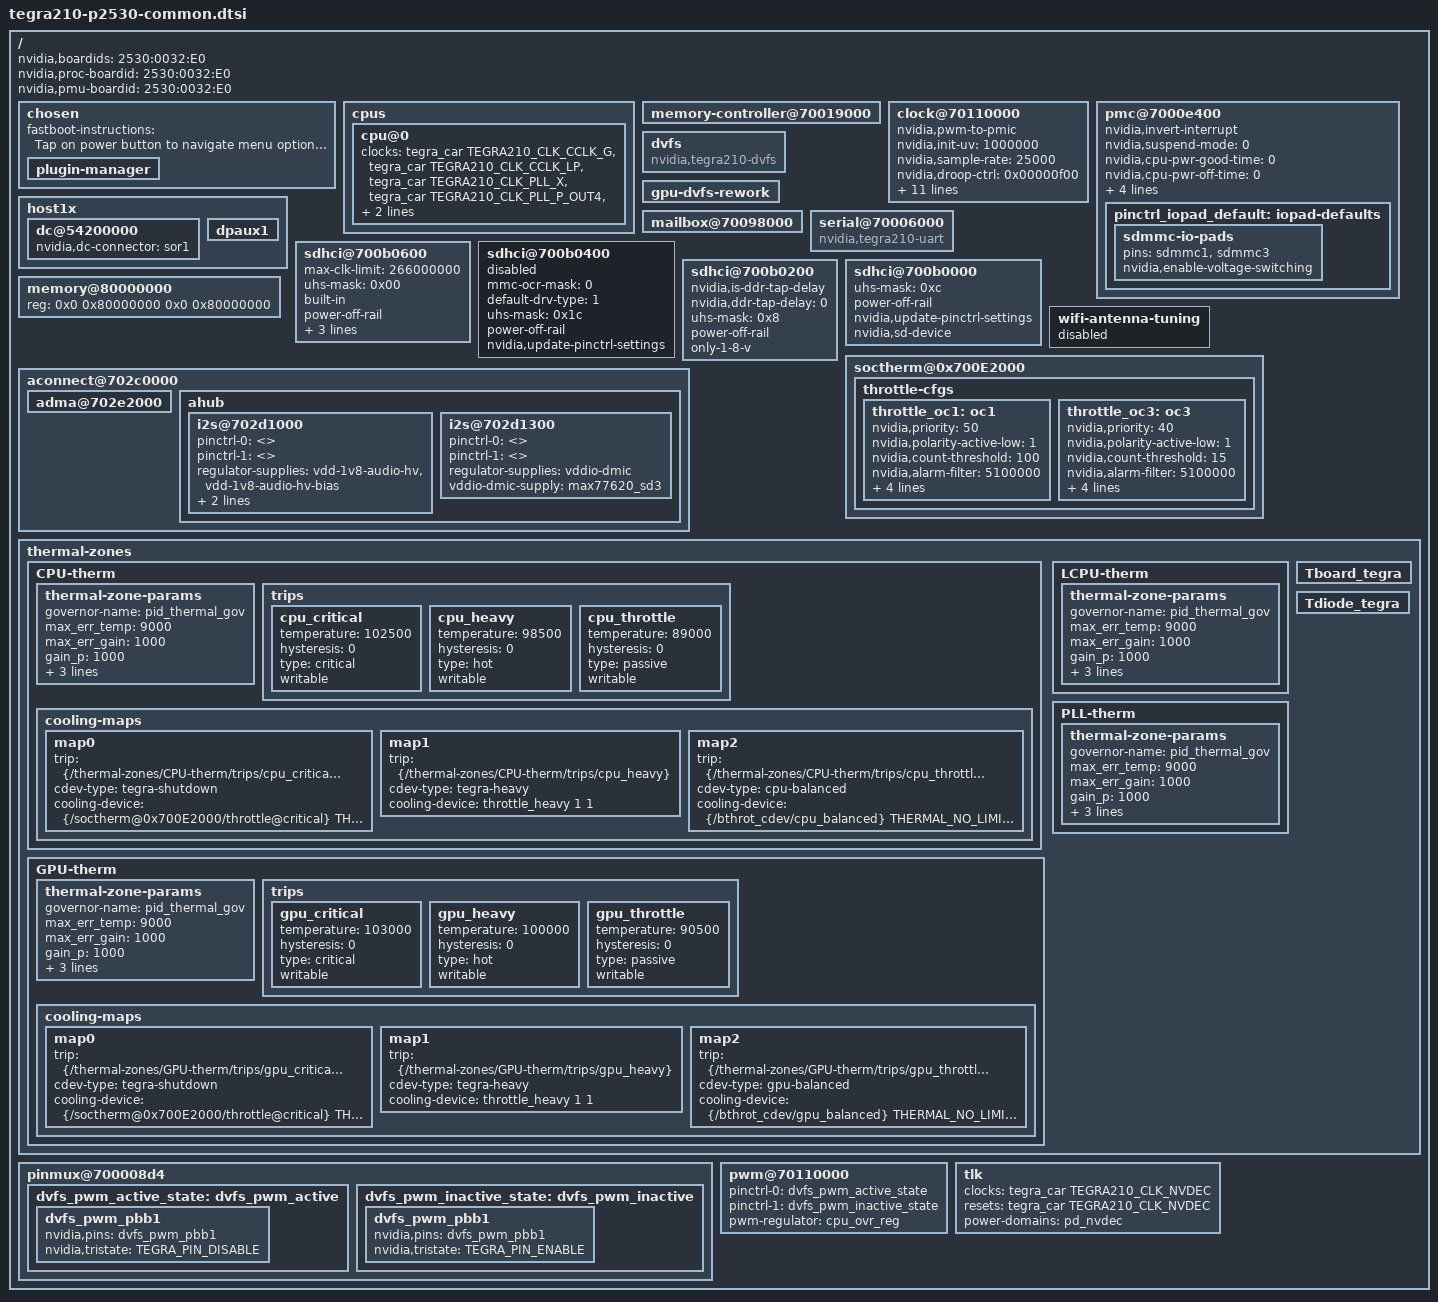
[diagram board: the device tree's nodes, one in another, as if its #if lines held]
/*
 * arch/arm64/boot/dts/tegra210-platforms/tegra210-p2530-common.dtsi
 *
 * Copyright (c) 2014 - 2017, NVIDIA CORPORATION.  All rights reserved.
 *
 * This program is free software; you can redistribute it and/or modify
 * it under the terms of the GNU General Public License as published by
 * the Free Software Foundation; version 2 of the License.
 *
 * This program is distributed in the hope that it will be useful, but WITHOUT
 * ANY WARRANTY; without even the implied warranty of MERCHANTABILITY or
 * FITNESS FOR A PARTICULAR PURPOSE.  See the GNU General Public License for
 * more details.
 *
 * You should have received a copy of the GNU General Public License along
 * with this program; if not, write to the Free Software Foundation, Inc.,
 * 51 Franklin Street, Fifth Floor, Boston, MA  02110-1301, USA.
 *
 */

#include <t210-common-platforms/tegra210-thermal-nct72-p2530.dtsi>
#include <tegra210-soc/tegra210-thermal-Tboard-Tdiode.dtsi>

/ {
	nvidia,boardids = "2530:0032:E0";
	nvidia,proc-boardid = "2530:0032:E0";
	nvidia,pmu-boardid = "2530:0032:E0";
	#address-cells = <2>;
	#size-cells = <2>;

	chosen {
		fastboot-instructions = "Tap on power button to navigate menu options.\nHold down power button for 2 sec and release for selecting an option\n";
		plugin-manager {
		};
	};

	cpus {
		cpu@0 {
			clocks = <&tegra_car TEGRA210_CLK_CCLK_G>,
				 <&tegra_car TEGRA210_CLK_CCLK_LP>,
				 <&tegra_car TEGRA210_CLK_PLL_X>,
				 <&tegra_car TEGRA210_CLK_PLL_P_OUT4>,
				 <&tegra_clk_dfll>;
			clock-names = "cpu_g", "cpu_lp", "pll_x", "pll_p", "dfll";
			clock-latency = <300000>;
		};
	};


	memory-controller@70019000 {
		status = "okay";
	};

	clock@70110000 {
		status = "okay";
		nvidia,pwm-to-pmic;
		nvidia,init-uv = <1000000>;
		nvidia,sample-rate = <25000>;
		nvidia,droop-ctrl = <0x00000f00>;
		nvidia,force-mode = <1>;
		nvidia,cf = <6>;
		nvidia,ci = <0>;
		nvidia,cg = <2>;
		nvidia,idle-override;
		nvidia,one-shot-calibrate;
		nvidia,pwm-period = <2500>; /* 2.5us */
		pinctrl-names = "dvfs_pwm_enable", "dvfs_pwm_disable";
		pinctrl-0 = <&dvfs_pwm_active_state>;
		pinctrl-1 = <&dvfs_pwm_inactive_state>;
		nvidia,align-offset-uv = <708000>;
		nvidia,align-step-uv = <19200>;
	};

	pmc@7000e400 {
		#nvidia,wake-cells = <3>;
		nvidia,invert-interrupt;
		nvidia,suspend-mode = <0>;
		nvidia,cpu-pwr-good-time = <0>;
		nvidia,cpu-pwr-off-time = <0>;
		nvidia,core-pwr-good-time = <4587 3876>;
		nvidia,core-pwr-off-time = <39065>;
		nvidia,core-power-req-active-high;
		nvidia,sys-clock-req-active-high;
		pinctrl_iopad_default:iopad-defaults {
			sdmmc-io-pads {
				pins = "sdmmc1", "sdmmc3";
				nvidia,enable-voltage-switching;
			};
		};
	};

	host1x {
		/* tegradc.0 */
		dc@54200000 {
			nvidia,dc-connector = <&sor1>;
		};

		dpaux1 {
			status = "okay";
		};
	};
	dvfs {
		compatible = "nvidia,tegra210-dvfs";
	};

	gpu-dvfs-rework {
		status = "okay";
	};

	mailbox@70098000 {
		status = "okay";
	};

	serial@70006000 {
		compatible = "nvidia,tegra210-uart", "nvidia,tegra114-hsuart", "nvidia,tegra20-uart";
		status = "okay";
	};

	sdhci@700b0600 {
		max-clk-limit = <266000000>;
		uhs-mask = <0x00>;
		built-in;
		power-off-rail;
		nvidia,enable-hs533-mode;
		only-1-8-v;
		pll_source = "pll_p", "pll_c4_out1";
		status = "okay";
	};

	sdhci@700b0400 {
		mmc-ocr-mask = <0>;
		default-drv-type = <1>;
		uhs-mask = <0x1c>;
		power-off-rail;
		nvidia,update-pinctrl-settings;
		status = "disabled";
	};

	sdhci@700b0200 {
		nvidia,is-ddr-tap-delay;
		nvidia,ddr-tap-delay = <0>;
		uhs-mask = <0x8>;
		power-off-rail;
		only-1-8-v;
		status = "okay";
	};

	sdhci@700b0000 {
		uhs-mask = <0xc>;
		power-off-rail;
		nvidia,update-pinctrl-settings;
		nvidia,sd-device;
		status = "okay";
	};

	memory@80000000 {
		device_type = "memory";
		reg = < 0x0 0x80000000 0x0 0x80000000 >;
	};

#if TEGRA_AUDIO_BUS_DT_VERSION >= DT_VERSION_2
	aconnect@702c0000 {
#endif
	adma@702e2000  {
		status = "okay";
	};

	ahub {
		i2s@702d1000 {
			pinctrl-names = "dap_active", "dap_inactive";
			pinctrl-0 = <>;
			pinctrl-1 = <>;
			regulator-supplies = "vdd-1v8-audio-hv", "vdd-1v8-audio-hv-bias";
			vdd-1v8-audio-hv-supply = <&max77620_sd3>;
			vdd-1v8-audio-hv-bias-supply = <&max77620_sd3>;
		};

		i2s@702d1300 {
			pinctrl-names = "dap_active", "dap_inactive";
			pinctrl-0 = <>;
			pinctrl-1 = <>;
			regulator-supplies = "vddio-dmic";
			vddio-dmic-supply = <&max77620_sd3>;
		};
	};
#if TEGRA_AUDIO_BUS_DT_VERSION >= DT_VERSION_2
	};
#endif

	wifi-antenna-tuning {
		status = "disabled";
	};

	soctherm@0x700E2000 {
		throttle-cfgs {
			throttle_oc1: oc1 {
				nvidia,priority = <50>;
				nvidia,polarity-active-low = <1>;
				nvidia,count-threshold = <100>;
				nvidia,alarm-filter = <5100000>;
				nvidia,alarm-period = <0>;
				nvidia,cpu-throt-percent = <75>;
				nvidia,gpu-throt-level =
					<TEGRA_SOCTHERM_THROT_LEVEL_MED>;
			};
			throttle_oc3: oc3 {
				nvidia,priority = <40>;
				nvidia,polarity-active-low = <1>;
				nvidia,count-threshold = <15>;
				nvidia,alarm-filter = <5100000>;
				nvidia,alarm-period = <0>;
				nvidia,cpu-throt-percent = <75>;
				nvidia,gpu-throt-level =
					<TEGRA_SOCTHERM_THROT_LEVEL_MED>;
			};
		};

	};

	thermal-zones {
		CPU-therm {
			thermal-zone-params {
				governor-name = "pid_thermal_gov";
				max_err_temp = <9000>;
				max_err_gain = <1000>;
				gain_p = <1000>;
				gain_d = <0>;
				up_compensation = <20>;
				down_compensation = <20>;
			};
			trips {
				cpu_critical {
					temperature = <102500>;
					hysteresis = <0>;
					type = "critical";
					writable;
				};
				cpu_heavy {
					temperature = <98500>;
					hysteresis = <0>;
					type = "hot";
					writable;
				};
				cpu_throttle {
					temperature = <89000>;
					hysteresis = <0>;
					type = "passive";
					writable;
				};
			};
			cooling-maps {
				map0 {
					trip = <&{/thermal-zones/CPU-therm/trips/cpu_critical}>;
					cdev-type = "tegra-shutdown";
					cooling-device = <&{/soctherm@0x700E2000/throttle@critical}
						THERMAL_NO_LIMIT THERMAL_NO_LIMIT>;
				};
				map1 {
					trip = <&{/thermal-zones/CPU-therm/trips/cpu_heavy}>;
					cdev-type = "tegra-heavy";
					cooling-device = <&throttle_heavy 1 1>;
				};
				map2 {
					trip = <&{/thermal-zones/CPU-therm/trips/cpu_throttle}>;
					cdev-type = "cpu-balanced";
					cooling-device = <&{/bthrot_cdev/cpu_balanced}
						THERMAL_NO_LIMIT THERMAL_NO_LIMIT>;
				};
			};
		};
		GPU-therm {
			thermal-zone-params {
				governor-name = "pid_thermal_gov";
				max_err_temp = <9000>;
				max_err_gain = <1000>;
				gain_p = <1000>;
				gain_d = <0>;
				up_compensation = <20>;
				down_compensation = <20>;
			};
			trips {
				gpu_critical {
					temperature = <103000>;
					hysteresis = <0>;
					type = "critical";
					writable;
				};
				gpu_heavy {
					temperature = <100000>;
					hysteresis = <0>;
					type = "hot";
					writable;
				};
				gpu_throttle {
					temperature = <90500>;
					hysteresis = <0>;
					type = "passive";
					writable;
				};
			};
			cooling-maps {
				map0 {
					trip = <&{/thermal-zones/GPU-therm/trips/gpu_critical}>;
					cdev-type = "tegra-shutdown";
					cooling-device = <&{/soctherm@0x700E2000/throttle@critical}
						THERMAL_NO_LIMIT THERMAL_NO_LIMIT>;
				};
				map1 {
					trip = <&{/thermal-zones/GPU-therm/trips/gpu_heavy}>;
					cdev-type = "tegra-heavy";
					cooling-device = <&throttle_heavy 1 1>;
				};
				map2 {
					trip = <&{/thermal-zones/GPU-therm/trips/gpu_throttle}>;
					cdev-type = "gpu-balanced";
					cooling-device = <&{/bthrot_cdev/gpu_balanced}
						THERMAL_NO_LIMIT THERMAL_NO_LIMIT>;
				};
			};
		};
		LCPU-therm {
			thermal-zone-params {
				governor-name = "pid_thermal_gov";
				max_err_temp = <9000>;
				max_err_gain = <1000>;
				gain_p = <1000>;
				gain_d = <0>;
				up_compensation = <20>;
				down_compensation = <20>;
			};
		};
		PLL-therm {
			thermal-zone-params {
				governor-name = "pid_thermal_gov";
				max_err_temp = <9000>;
				max_err_gain = <1000>;
				gain_p = <1000>;
				gain_d = <0>;
				up_compensation = <20>;
				down_compensation = <20>;
			};
		};

		Tboard_tegra {
			status = "okay";
		};
		Tdiode_tegra {
			status = "okay";
		};
	};

	pinmux@700008d4 {
		dvfs_pwm_active_state: dvfs_pwm_active {
			dvfs_pwm_pbb1 {
				nvidia,pins = "dvfs_pwm_pbb1";
				nvidia,tristate = <TEGRA_PIN_DISABLE>;
			};
		};

		dvfs_pwm_inactive_state: dvfs_pwm_inactive {
			dvfs_pwm_pbb1 {
				nvidia,pins = "dvfs_pwm_pbb1";
				nvidia,tristate = <TEGRA_PIN_ENABLE>;
			};
		};
	};

	pwm@70110000 {
		pinctrl-0 = <&dvfs_pwm_active_state>;
		pinctrl-1 = <&dvfs_pwm_inactive_state>;
		pwm-regulator = <&cpu_ovr_reg>;
		status = "okay";
	};

	tlk {
		clocks = <&tegra_car TEGRA210_CLK_NVDEC>;
		clock-names = "nvdec";
		resets = <&tegra_car TEGRA210_CLK_NVDEC>;
		reset-names = "nvdec";
		power-domains = <&pd_nvdec>;
	};
};

